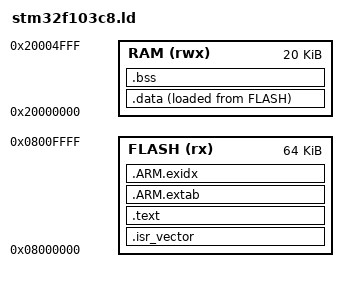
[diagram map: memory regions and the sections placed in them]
/* Generated by HALA SIM. Regenerate from the project context menu. */
ENTRY(Reset_Handler)
MEMORY
{
  FLASH (rx)  : ORIGIN = 0x08000000, LENGTH = 64K
  RAM   (rwx) : ORIGIN = 0x20000000, LENGTH = 20K
}
_estack = ORIGIN(RAM) + LENGTH(RAM);
SECTIONS
{
  .isr_vector : { . = ALIGN(4); KEEP(*(.isr_vector)) } > FLASH
  .text : { . = ALIGN(4); *(.text*) *(.rodata*) } > FLASH
  .ARM.extab : { *(.ARM.extab*) } > FLASH
  .ARM.exidx : { __exidx_start = .; *(.ARM.exidx*) __exidx_end = .; } > FLASH
  _sidata = LOADADDR(.data);
  .data : { . = ALIGN(4); _sdata = .; *(.data*) . = ALIGN(4); _edata = .; } > RAM AT> FLASH
  .bss : { . = ALIGN(4); _sbss = .; *(.bss*) *(COMMON) . = ALIGN(4); _ebss = .; } > RAM
  /DISCARD/ : { *(.comment) *(.note*) }
}
